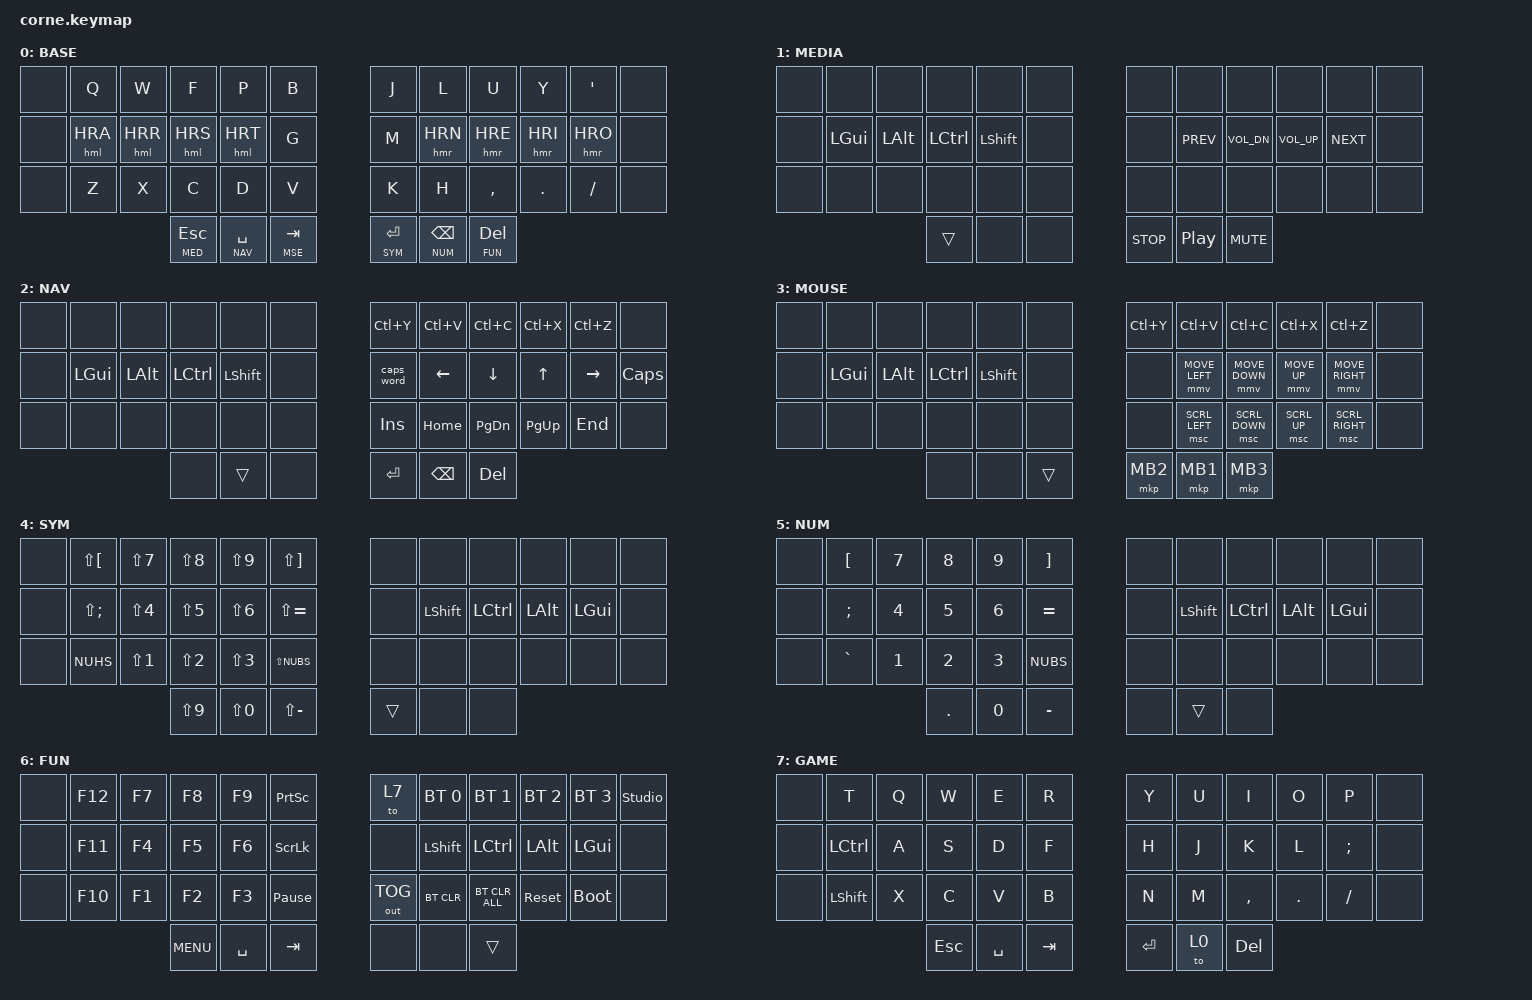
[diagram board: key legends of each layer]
/*
 * Copyright (c) 2020 The ZMK Contributors
 *
 * SPDX-License-Identifier: MIT
 */

#include <behaviors.dtsi>
#include <dt-bindings/zmk/keys.h>
#include <dt-bindings/zmk/bt.h>
#include <dt-bindings/zmk/outputs.h>
#include <dt-bindings/zmk/pointing.h>

// three letter layer names
#define BSE 0
#define MED 1
#define NAV 2
#define MSE 3
#define SYM 4
#define NUM 5
#define FUN 6

//define short homerow mod keys 
#define HRA LGUI A
#define HRR LALT R
#define HRS LCTRL S
#define HRT LSHIFT T

#define HRN LSHIFT N
#define HRE LCTRL E
#define HRI LALT I
#define HRO LGUI O

// key positions for hold-trigger-key-positions
#define KEYS_L 0 1 2 3 4 5 12 13 14 15 16 17 24 25 26 27 28 29
#define KEYS_R 6 7 8 9 10 11 18 19 20 21 22 23 30 31 32 33 34 35
#define THUMBS 36 37 38 39 40 41

/ {
        behaviors {
            hml: homerow_mods_left {
                compatible = "zmk,behavior-hold-tap";
                #binding-cells = <2>;
                flavor = "balanced";
                tapping-term-ms = <200>;
                quick-tap-ms = <175>;
                require-prior-idle-ms = <150>;
                hold-trigger-key-positions = <KEYS_R THUMBS>;
                hold-trigger-on-release;
                bindings = <&kp>, <&kp>;
            };
            hmr: homerow_mods_right {
                compatible = "zmk,behavior-hold-tap";
                #binding-cells = <2>;
                flavor = "balanced";
                tapping-term-ms = <200>;
                quick-tap-ms = <175>;
                require-prior-idle-ms = <150>;
                hold-trigger-key-positions = <KEYS_L THUMBS>;
                hold-trigger-on-release;
                bindings = <&kp>, <&kp>;
            };
        };

        combos {
            compatible = "zmk,combos";
            combo_esc {
                timeout-ms = <50>;
                key-positions = <2 3>;          // W + F
                require-prior-idle-ms = <150>;
                bindings = <&kp ESC>;
            };
            combo_bspc {
                timeout-ms = <50>;
                key-positions = <8 9>;          // U + Y
                require-prior-idle-ms = <150>;
                bindings = <&kp BSPC>;
            };
        };

        keymap {
                compatible = "zmk,keymap";

                default_layer {
                        display-name = "BASE";
// ----------------------------------------------------------------------
// | |  Q  |  W  |  F  |  P  |  B  |   |  J  |  L   |  U  |  Y  |  '  | |
// | |  A  |  R  |  S  |  T  |  G  |   |  M  |  N   |  E  |  I  |  O  | |
// | |  Z  |  X  |  C  |  D  |  V  |   |  K  |  H   |  ,  |  .  |  /  | |
//               | ESC | SPC | TAB |   | RET | BSPC | DEL |   (hold: MED NAV MSE | SYM NUM FUN)
// combos: W+F = ESC, U+Y = BSPC
                        bindings = <
   	&none 	&kp Q   	&kp W   	&kp F   	&kp P   	&kp B   	&kp J 	&kp L   	&kp U   	&kp Y   	&kp SQT 	&none
   	&none 	&hml HRA 	&hml HRR 	&hml HRS 	&hml HRT 	&kp G   	&kp M 	&hmr HRN 	&hmr HRE 	&hmr HRI 	&hmr HRO 	&none
   	&none 	&kp Z   	&kp X   	&kp C   	&kp D   	&kp V   	&kp K 	&kp H   	&kp COMMA 	&kp DOT 	&kp FSLH 	&none
         	            &lt MED ESC &lt NAV SPACE  &lt MSE TAB    	                        &lt SYM RET   	&lt NUM BSPC	&lt FUN DEL
                        >;
                };
                media_layer {
                        display-name = "MEDIA";
                        bindings = <
   &none &none        &none        &none        &none        &none        &none        &none        &none        &none        &none        &none
   &none &kp LGUI     &kp LALT     &kp LCTRL    &kp LSHIFT   &none        &none        &kp C_PREV   &kp C_VOL_DN &kp C_VOL_UP &kp C_NEXT   &none
   &none &none        &none        &none        &none        &none        &none        &none        &none        &none        &none        &none
                                   &trans       &none        &none        &kp C_STOP   &kp C_PP     &kp C_MUTE
                        >;
                };
                nav_layer {
                        display-name = "NAV";
                        bindings = <
   &none &none        &none        &none        &none        &none        &kp LC(Y)     &kp LC(V)    &kp LC(C)    &kp LC(X)    &kp LC(Z)     &none
   &none &kp LGUI     &kp LALT     &kp LCTRL    &kp LSHIFT   &none        &caps_word    &kp LEFT     &kp DOWN     &kp UP       &kp RIGHT    &kp CAPSLOCK
   &none &none        &none        &none        &none        &none        &kp INSERT    &kp HOME     &kp PG_DN    &kp PG_UP    &kp END      &none
                                   &none        &trans       &none      &kp RET       &kp BSPC     &kp DEL
                        >;
                };
                mouse_layer {
                        display-name = "MOUSE";
                        bindings = <
   &none &none        &none        &none        &none        &none        &kp LC(Y)     &kp LC(V)       &kp LC(C)       &kp LC(X)     &kp LC(Z)        &none
   &none &kp LGUI     &kp LALT     &kp LCTRL    &kp LSHIFT   &none        &none         &mmv  MOVE_LEFT &mmv  MOVE_DOWN &mmv  MOVE_UP &mmv  MOVE_RIGHT &none
   &none &none        &none        &none        &none        &none        &none         &msc SCRL_LEFT  &msc SCRL_DOWN  &msc SCRL_UP  &msc SCRL_RIGHT  &none
                                   &none        &none        &trans       &mkp MB2      &mkp MB1        &mkp MB3
                        >;
                };
                symbol_layer {
                        display-name = "SYM";
                        bindings = <
   &none &kp LS(LBKT) &kp LS(N7)   &kp LS(N8)   &kp LS(N9)   &kp LS(RBKT)  &none        &none        &none        &none        &none        &none
   &none &kp LS(SEMI) &kp LS(N4)   &kp LS(N5)   &kp LS(N6)   &kp LS(EQUAL) &none        &kp LSHIFT   &kp LCTRL    &kp LALT     &kp LGUI     &none
   &none &kp NUHS &kp LS(N1)   &kp LS(N2)   &kp LS(N3)   &kp LS(NUBS)  &none        &none        &none        &none        &none        &none
                                   &kp LS(N9)   &kp LS(N0) &kp LS(MINUS) &trans       &none        &none
                        >;
                };
                number_layer {
                        display-name = "NUM";
                        bindings = <
   &none &kp LBKT &kp N7   &kp N8   &kp N9   &kp RBKT  &none        &none        &none        &none        &none        &none
   &none &kp SEMI &kp N4   &kp N5   &kp N6   &kp EQUAL &none        &kp LSHIFT   &kp LCTRL    &kp LALT     &kp LGUI     &none
   &none &kp GRAVE &kp N1  &kp N2   &kp N3   &kp NUBS  &none        &none        &none        &none        &none        &none
                                    &kp DOT  &kp N0    &kp MINUS    &none        &trans       &none
                        >;
                };
                function_layer {
                        display-name = "FUN";
                        bindings = <
   &none &kp F12  &kp F7   &kp F8   &kp F9   &kp PSCRN         &to 7        &bt BT_SEL 0 &bt BT_SEL 1 &bt BT_SEL 2 &bt BT_SEL 3 &studio_unlock
   &none &kp F11  &kp F4   &kp F5   &kp F6   &kp SCROLLLOCK    &none        &kp LSHIFT   &kp LCTRL    &kp LALT     &kp LGUI     &none
   &none &kp F10  &kp F1   &kp F2   &kp F3   &kp PAUSE_BREAK   &out OUT_TOG &bt BT_CLR   &bt BT_CLR_ALL &sys_reset &bootloader &none
                             &kp C_MENU &kp SPACE  &kp TAB     &none        &none        &trans
                        >;
                };
                gaming_layer {
                        display-name = "GAME";
// ----------------------------------------------------------------------
// | |  Q  |  q  |  w  |  e  |  r  |   |  J  |  L   |  U  |  Y  |  '  | |
// | |  A  |  a  |  s  |  d  |  f  |   |  M  |  N   |  E  |  I  |  O  | |
// | |  Z  |  X  |  C  |  D  |  V  |   |  K  |  H   |  ,  |  .  |  /  | |
//               | GUI | LWR | SPC |   | ENT | RSE  | ALT |
                        bindings = <
   	&none 	&kp T       &kp Q   &kp W   	&kp E   	&kp R   	&kp Y 	&kp U   	&kp I   	&kp O   	&kp P  	    &none
   	&none 	&kp LCTRL   &kp A   &kp S 	&kp D    	&kp F   	&kp H 	&kp J    	&kp K   	&kp L   	&kp SEMI 	&none
   	&none 	&kp LSHIFT  &kp X   &kp C   	&kp V   	&kp B   	&kp N 	&kp M   	&kp COMMA 	&kp DOT 	&kp FSLH 	&none
         	            &kp ESC &kp SPACE &kp TAB   	&kp RET     &to 0 	&kp DEL
                        >;
                };
        };
};
